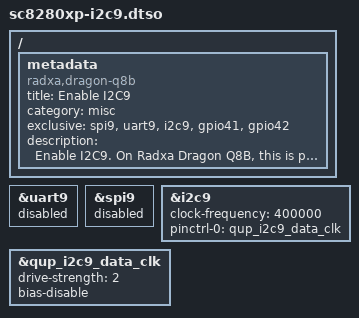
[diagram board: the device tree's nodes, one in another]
// SPDX-License-Identifier: BSD-3-Clause
/*
 * Copyright (c) 2026 Radxa Computer (Shenzhen) Co., Ltd.
 */

/dts-v1/;
/plugin/;

/ {
	metadata {
		title = "Enable I2C9";
		compatible = "radxa,dragon-q8b";
		category = "misc";
		exclusive = "spi9", "uart9", "i2c9", "gpio41", "gpio42";
		description = "Enable I2C9.
On Radxa Dragon Q8B, this is pin 5(scl), 3(sda).";
	};
};

&uart9 {
	status = "disabled";
};

&spi9 {
	status = "disabled";
};

&i2c9 {
	clock-frequency = <400000>;

	pinctrl-0 = <&qup_i2c9_data_clk>;
	pinctrl-names = "default";

	status = "okay";
};

&qup_i2c9_data_clk {
	drive-strength = <2>;
	bias-disable;
};
